# STM32WL5x_CM0P register map
File version: 1.9
CPU: CM0 r0p1, little endian, MPU, no FPU, 4 interrupt priority bits
Registers are 32-bit, read-write, reset 0x0 unless marked. A register's access mark holds for its fields unless they carry their own. Offsets are from the block's base; [hi:lo] are bit positions; {n}, {i} and the like mark numbered series; 'fields as' and 'values as' point back to an identical list.

## HSEM — Hardware semaphore
Base 0x58001400
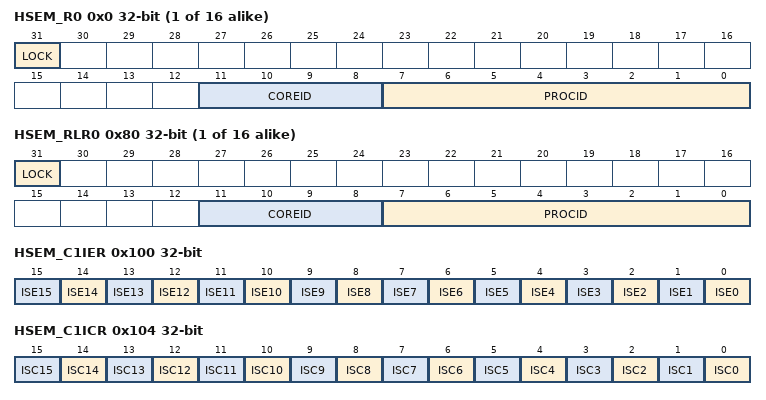
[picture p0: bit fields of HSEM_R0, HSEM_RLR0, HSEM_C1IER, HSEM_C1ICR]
{0x0+4i} HSEM_R{i} (i=0..15) — HSEM register HSEM_R0 HSEM_R31
  [31] LOCK — Lock indication
  [11:8] COREID
  [7:0] PROCID — Semaphore ProcessID
{0x80+4i} HSEM_RLR{i} ro (i=0..15) — HSEM Read lock register
  fields as HSEM_R0
0x100 HSEM_C1IER — HSEM Interrupt enable register
  [n] ISE{n} (n=0..15) — Interrupt semaphore n enable bit
0x104 HSEM_C1ICR — HSEM Interrupt clear register
  [n] ISC{n} (n=0..15) — Interrupt(N) semaphore n clear bit
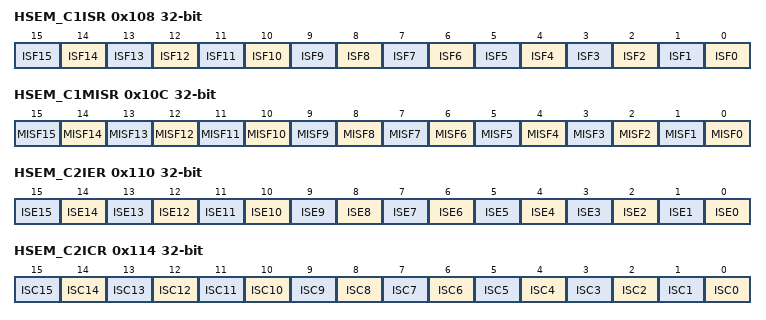
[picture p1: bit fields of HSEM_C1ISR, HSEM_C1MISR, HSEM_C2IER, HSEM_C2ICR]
0x108 HSEM_C1ISR ro — HSEM Interrupt status register
  [n] ISF{n} (n=0..15) — Interrupt(N) semaphore n status bit before enable (mask)
0x10C HSEM_C1MISR ro — HSEM Masked interrupt status register
  [n] MISF{n} (n=0..15) — masked interrupt(N) semaphore n status bit after enable (mask)
0x110 HSEM_C2IER — HSEM Interrupt enable register
  [n] ISE{n} (n=0..15) — Interrupt semaphore n enable bit
0x114 HSEM_C2ICR ro — HSEM Interrupt clear register
  [n] ISC{n} (n=0..15) — Interrupt(N) semaphore n clear bit
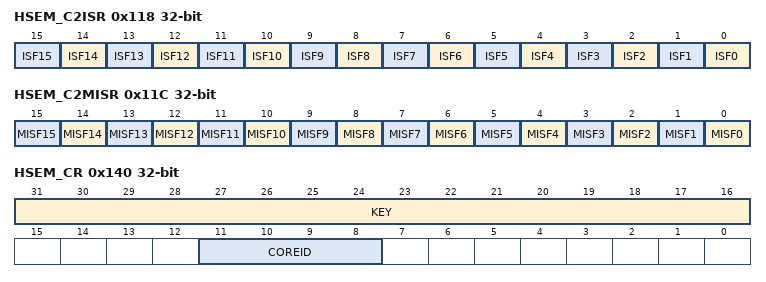
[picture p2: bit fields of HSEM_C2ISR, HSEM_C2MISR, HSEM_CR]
0x118 HSEM_C2ISR ro — HSEM Interrupt status register
  fields as HSEM_C1ISR
0x11C HSEM_C2MISR ro — HSEM Masked interrupt status register
  fields as HSEM_C1MISR
0x140 HSEM_CR wo — HSEM Clear register
  [31:16] KEY — Semaphore clear Key
  [11:8] COREID
0x144 HSEM_KEYR — HSEM Interrupt clear register
  [31:16] KEY — Semaphore Clear Key

## IPCC — Inter Processor communication controller
Base 0x58000C00
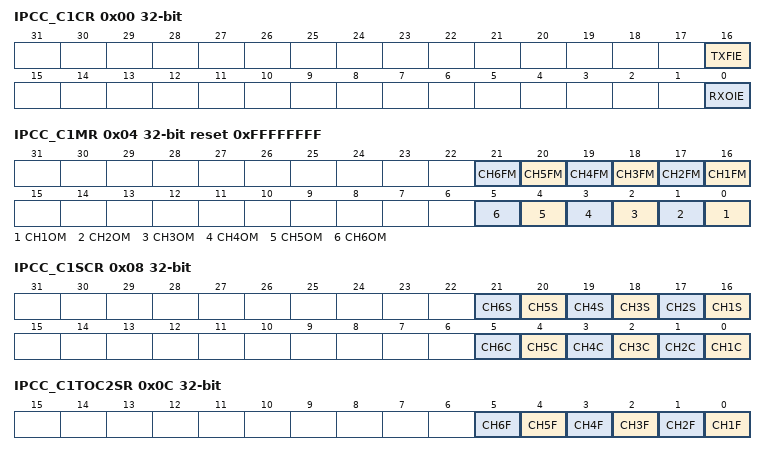
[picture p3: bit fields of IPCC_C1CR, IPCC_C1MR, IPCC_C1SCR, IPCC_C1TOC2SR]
0x00 IPCC_C1CR — IPCC Processor 1 control register
  [16] TXFIE, [0] RXOIE
0x04 IPCC_C1MR reset 0xFFFFFFFF — IPCC Processor 1 mask register
  [n+15] CH{n}FM (n=1..6), [n-1] CH{n}OM (n=1..6)
0x08 IPCC_C1SCR — Reading this register will always return 0x0000 0000.
  [n+15] CH{n}S (n=1..6), [n-1] CH{n}C (n=1..6)
0x0C IPCC_C1TOC2SR ro — IPCC processor 1 to processor 2 status register
  [n-1] CH{n}F (n=1..6)
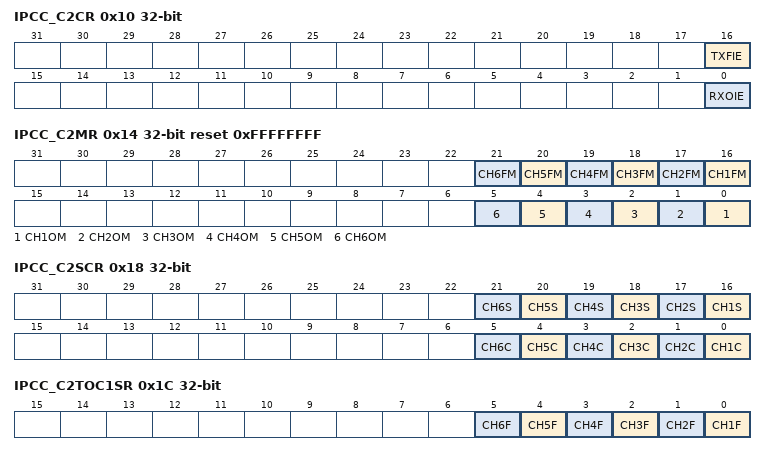
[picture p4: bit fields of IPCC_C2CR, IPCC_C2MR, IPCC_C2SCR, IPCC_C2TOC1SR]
0x10 IPCC_C2CR — IPCC Processor 2 control register
  [16] TXFIE, [0] RXOIE
0x14 IPCC_C2MR reset 0xFFFFFFFF — IPCC Processor 2 mask register
  [n+15] CH{n}FM (n=1..6), [n-1] CH{n}OM (n=1..6)
0x18 IPCC_C2SCR — Reading this register will always return 0x0000 0000.
  [n+15] CH{n}S (n=1..6), [n-1] CH{n}C (n=1..6)
0x1C IPCC_C2TOC1SR ro — IPCC processor 2 to processor 1 status register
  [n-1] CH{n}F (n=1..6)
0x3F0 IPCC_HWCFGR ro reset 0x6 — IPCC Hardware configuration register
  [7:0] CHANNELS
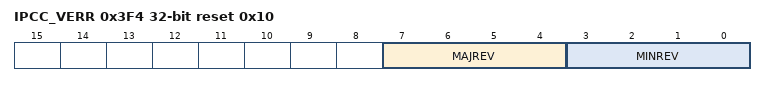
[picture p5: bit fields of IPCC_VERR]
0x3F4 IPCC_VERR ro reset 0x10 — IPCC IP Version register
  [7:4] MAJREV, [3:0] MINREV
0x3F8 IPCC_IPIDR ro reset 0x100071 — IPCC IP Identification register
  [31:0] ID
0x3FC IPCC_SIDR ro reset 0xA3C5DD01 — IPCC Size ID register
  [31:0] SID

## IWDG — Independent watchdog
Base 0x40003000
0x00 KR wo — Key register
  [15:0] KEY — Key value (write only, read 0x0000)
0x04 PR reset 0x7 — Prescaler register
  [2:0] PR — Prescaler divider
0x08 RLR reset 0xFFF — Reload register
  [11:0] RL — Watchdog counter reload value
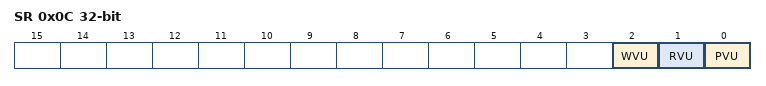
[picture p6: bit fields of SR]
0x0C SR ro — Status register
  [2] WVU — Watchdog counter window value update
  [1] RVU — Watchdog counter reload value update
  [0] PVU — Watchdog prescaler value update
0x10 WINR reset 0xFFF — Window register
  [11:0] WIN — Watchdog counter window value

## LPTIM1 — Low-power timer
Base 0x40007C00
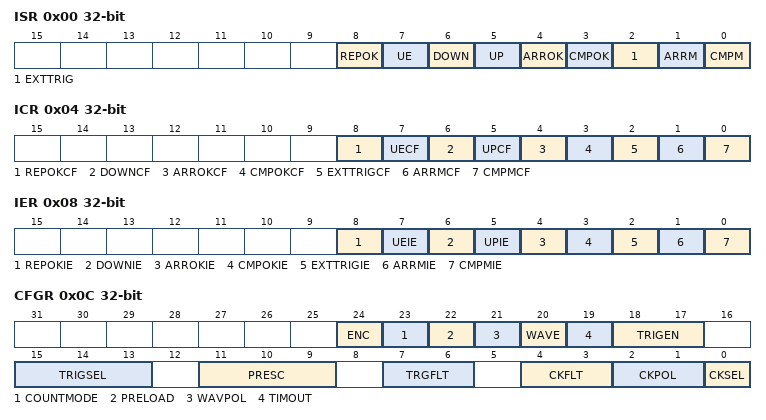
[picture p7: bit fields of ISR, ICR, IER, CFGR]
0x00 ISR ro — interrupt and status register
  [8] REPOK — Repetition register update Ok
  [7] UE — LPTIM update event occurred
  [6] DOWN — Counter direction change up to down
  [5] UP — Counter direction change down to up
  [4] ARROK — Autoreload register update OK
  [3] CMPOK — Compare register update OK
  [2] EXTTRIG — External trigger edge event
  [1] ARRM — Autoreload match
  [0] CMPM — Compare match
0x04 ICR wo — interrupt clear register
  [8] REPOKCF — Repetition register update OK clear flag
  [7] UECF — Update event clear flag
  [6] DOWNCF — Direction change to down Clear Flag
  [5] UPCF — Direction change to UP Clear Flag
  [4] ARROKCF — Autoreload register update OK Clear Flag
  [3] CMPOKCF — Compare register update OK Clear Flag
  [2] EXTTRIGCF — External trigger valid edge Clear Flag
  [1] ARRMCF — Autoreload match Clear Flag
  [0] CMPMCF — compare match Clear Flag
0x08 IER — interrupt enable register
  [8] REPOKIE — Repetition register update OK interrupt Enable
  [7] UEIE — Update event interrupt enable
  [6] DOWNIE — Direction change to down Interrupt Enable
  [5] UPIE — Direction change to UP Interrupt Enable
  [4] ARROKIE — Autoreload register update OK Interrupt Enable
  [3] CMPOKIE — Compare register update OK Interrupt Enable
  [2] EXTTRIGIE — External trigger valid edge Interrupt Enable
  [1] ARRMIE — Autoreload match Interrupt Enable
  [0] CMPMIE — Compare match Interrupt Enable
0x0C CFGR — configuration register
  [24] ENC, [23] COUNTMODE, [22] PRELOAD, [21] WAVPOL, [20] WAVE, [19] TIMOUT, [18:17] TRIGEN, [15:13] TRIGSEL, [11:9] PRESC, [7:6] TRGFLT, [4:3] CKFLT, [2:1] CKPOL, [0] CKSEL
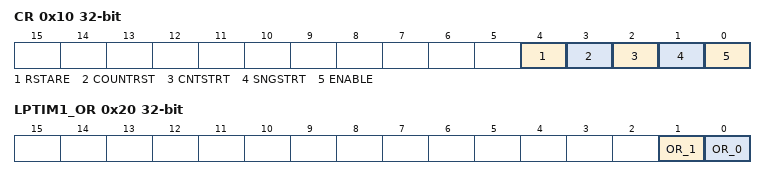
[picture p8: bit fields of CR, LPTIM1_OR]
0x10 CR — control register
  [4] RSTARE, [3] COUNTRST, [2] CNTSTRT, [1] SNGSTRT, [0] ENABLE
0x14 CMP — compare register
  [15:0] CMP
0x18 ARR reset 0x1 — autoreload register
  [15:0] ARR — Auto reload value
0x1C CNT ro — counter register
  [15:0] CNT — Counter value
0x20 LPTIM1_OR — option register
  [1] OR_1 — Option register bit 1
  [0] OR_0 — Option register bit 0
0x28 RCR — repetition register
  [7:0] REP — Repetition register value

## LPTIM2 — Low-power timer
Base 0x40009400
Registers as LPTIM1 (with LPTIM1 read as LPTIM2).

## LPTIM3 — Low-power timer
Base 0x40009800
Registers as LPTIM1 (with LPTIM1 read as LPTIM3).
